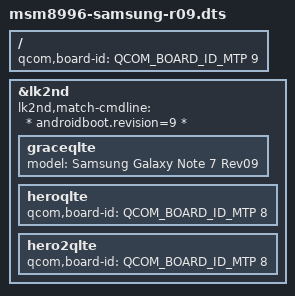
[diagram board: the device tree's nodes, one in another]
// SPDX-License-Identifier: BSD-3-Clause

#include "msm8996-samsung.dtsi"

/ {
	qcom,board-id = <QCOM_BOARD_ID_MTP 9>;
};

&lk2nd {
	lk2nd,match-cmdline = "* androidboot.revision=9 *";

	graceqlte {
		model = "Samsung Galaxy Note 7 Rev09";
	};

	heroqlte {
		qcom,board-id = <QCOM_BOARD_ID_MTP 8>;
	};

	hero2qlte {
		qcom,board-id = <QCOM_BOARD_ID_MTP 8>;
	};
};
